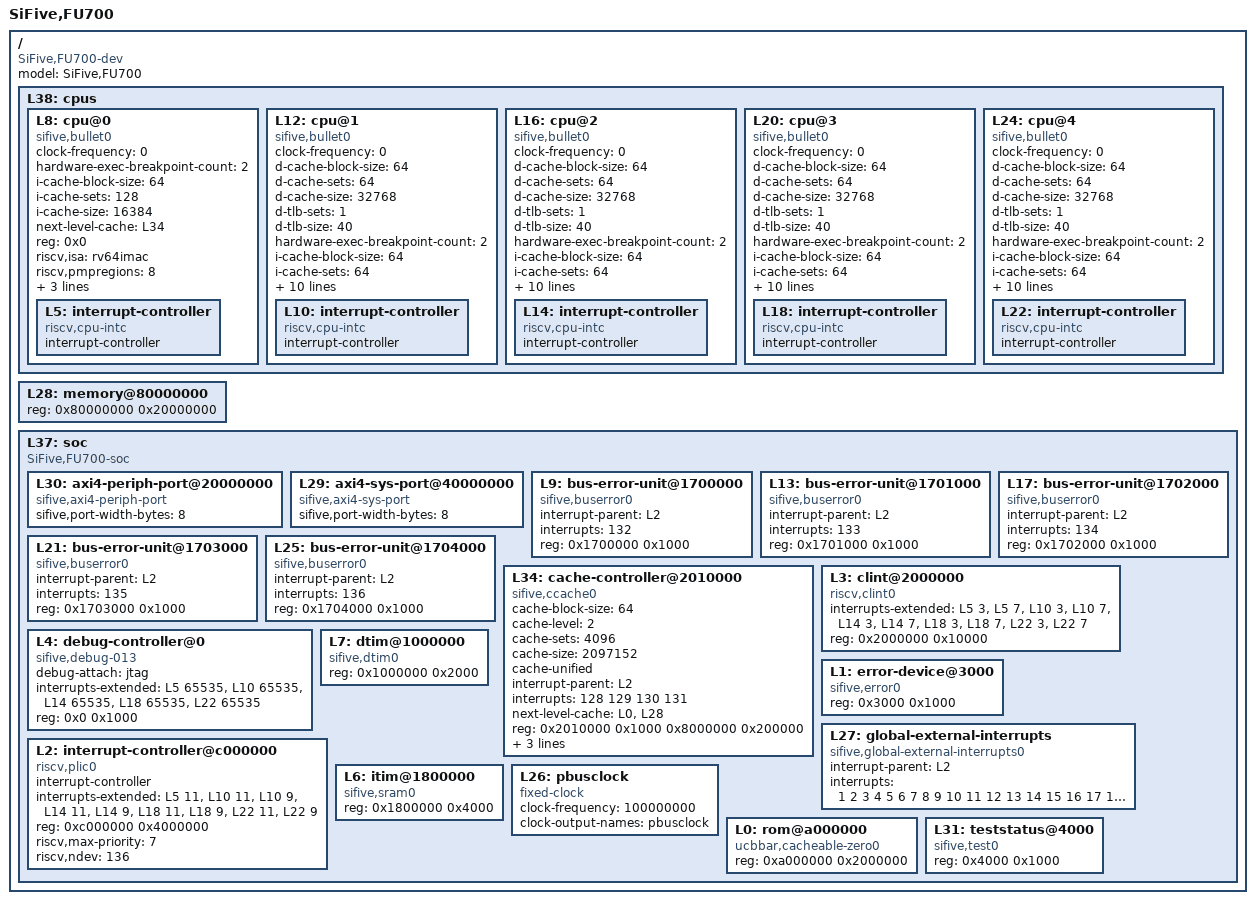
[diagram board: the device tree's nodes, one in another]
/dts-v1/;

/ {
	#address-cells = <1>;
	#size-cells = <1>;
	compatible = "SiFive,FU700-dev", "fu700-dev", "sifive-dev";
	model = "SiFive,FU700";
	L38: cpus {
		#address-cells = <1>;
		#size-cells = <0>;
		L8: cpu@0 {
			clock-frequency = <0>;
			compatible = "sifive,bullet0", "riscv";
			device_type = "cpu";
			hardware-exec-breakpoint-count = <2>;
			i-cache-block-size = <64>;
			i-cache-sets = <128>;
			i-cache-size = <16384>;
			next-level-cache = <&L34>;
			reg = <0x0>;
			riscv,isa = "rv64imac";
			riscv,pmpregions = <8>;
			sifive,dtim = <&L7>;
			sifive,itim = <&L6>;
			status = "okay";
			timebase-frequency = <1000000>;
			L5: interrupt-controller {
				#interrupt-cells = <1>;
				compatible = "riscv,cpu-intc";
				interrupt-controller;
			};
		};
		L12: cpu@1 {
			clock-frequency = <0>;
			compatible = "sifive,bullet0", "riscv";
			d-cache-block-size = <64>;
			d-cache-sets = <64>;
			d-cache-size = <32768>;
			d-tlb-sets = <1>;
			d-tlb-size = <40>;
			device_type = "cpu";
			hardware-exec-breakpoint-count = <2>;
			i-cache-block-size = <64>;
			i-cache-sets = <64>;
			i-cache-size = <32768>;
			i-tlb-sets = <1>;
			i-tlb-size = <40>;
			mmu-type = "riscv,sv39";
			next-level-cache = <&L34>;
			reg = <0x1>;
			riscv,isa = "rv64imafdc";
			riscv,pmpregions = <8>;
			status = "okay";
			timebase-frequency = <1000000>;
			tlb-split;
			L10: interrupt-controller {
				#interrupt-cells = <1>;
				compatible = "riscv,cpu-intc";
				interrupt-controller;
			};
		};
		L16: cpu@2 {
			clock-frequency = <0>;
			compatible = "sifive,bullet0", "riscv";
			d-cache-block-size = <64>;
			d-cache-sets = <64>;
			d-cache-size = <32768>;
			d-tlb-sets = <1>;
			d-tlb-size = <40>;
			device_type = "cpu";
			hardware-exec-breakpoint-count = <2>;
			i-cache-block-size = <64>;
			i-cache-sets = <64>;
			i-cache-size = <32768>;
			i-tlb-sets = <1>;
			i-tlb-size = <40>;
			mmu-type = "riscv,sv39";
			next-level-cache = <&L34>;
			reg = <0x2>;
			riscv,isa = "rv64imafdc";
			riscv,pmpregions = <8>;
			status = "okay";
			timebase-frequency = <1000000>;
			tlb-split;
			L14: interrupt-controller {
				#interrupt-cells = <1>;
				compatible = "riscv,cpu-intc";
				interrupt-controller;
			};
		};
		L20: cpu@3 {
			clock-frequency = <0>;
			compatible = "sifive,bullet0", "riscv";
			d-cache-block-size = <64>;
			d-cache-sets = <64>;
			d-cache-size = <32768>;
			d-tlb-sets = <1>;
			d-tlb-size = <40>;
			device_type = "cpu";
			hardware-exec-breakpoint-count = <2>;
			i-cache-block-size = <64>;
			i-cache-sets = <64>;
			i-cache-size = <32768>;
			i-tlb-sets = <1>;
			i-tlb-size = <40>;
			mmu-type = "riscv,sv39";
			next-level-cache = <&L34>;
			reg = <0x3>;
			riscv,isa = "rv64imafdc";
			riscv,pmpregions = <8>;
			status = "okay";
			timebase-frequency = <1000000>;
			tlb-split;
			L18: interrupt-controller {
				#interrupt-cells = <1>;
				compatible = "riscv,cpu-intc";
				interrupt-controller;
			};
		};
		L24: cpu@4 {
			clock-frequency = <0>;
			compatible = "sifive,bullet0", "riscv";
			d-cache-block-size = <64>;
			d-cache-sets = <64>;
			d-cache-size = <32768>;
			d-tlb-sets = <1>;
			d-tlb-size = <40>;
			device_type = "cpu";
			hardware-exec-breakpoint-count = <2>;
			i-cache-block-size = <64>;
			i-cache-sets = <64>;
			i-cache-size = <32768>;
			i-tlb-sets = <1>;
			i-tlb-size = <40>;
			mmu-type = "riscv,sv39";
			next-level-cache = <&L34>;
			reg = <0x4>;
			riscv,isa = "rv64imafdc";
			riscv,pmpregions = <8>;
			status = "okay";
			timebase-frequency = <1000000>;
			tlb-split;
			L22: interrupt-controller {
				#interrupt-cells = <1>;
				compatible = "riscv,cpu-intc";
				interrupt-controller;
			};
		};
	};
	L28: memory@80000000 {
		device_type = "memory";
		reg = <0x80000000 0x20000000>;
	};
	L37: soc {
		#address-cells = <1>;
		#size-cells = <1>;
		compatible = "SiFive,FU700-soc", "fu700-soc", "sifive-soc", "simple-bus";
		ranges;
		L30: axi4-periph-port@20000000 {
			#address-cells = <1>;
			#size-cells = <1>;
			compatible = "sifive,axi4-periph-port", "sifive,axi4-port", "sifive,periph-port", "simple-external-bus", "simple-bus";
			ranges = <0x20000000 0x20000000 0x10000000>;
			sifive,port-width-bytes = <8>;
		};
		L29: axi4-sys-port@40000000 {
			#address-cells = <1>;
			#size-cells = <1>;
			compatible = "sifive,axi4-sys-port", "sifive,axi4-port", "sifive,sys-port", "simple-external-bus", "simple-bus";
			ranges = <0x40000000 0x40000000 0x10000000>;
			sifive,port-width-bytes = <8>;
		};
		L9: bus-error-unit@1700000 {
			compatible = "sifive,buserror0";
			interrupt-parent = <&L2>;
			interrupts = <132>;
			reg = <0x1700000 0x1000>;
			reg-names = "control";
		};
		L13: bus-error-unit@1701000 {
			compatible = "sifive,buserror0";
			interrupt-parent = <&L2>;
			interrupts = <133>;
			reg = <0x1701000 0x1000>;
			reg-names = "control";
		};
		L17: bus-error-unit@1702000 {
			compatible = "sifive,buserror0";
			interrupt-parent = <&L2>;
			interrupts = <134>;
			reg = <0x1702000 0x1000>;
			reg-names = "control";
		};
		L21: bus-error-unit@1703000 {
			compatible = "sifive,buserror0";
			interrupt-parent = <&L2>;
			interrupts = <135>;
			reg = <0x1703000 0x1000>;
			reg-names = "control";
		};
		L25: bus-error-unit@1704000 {
			compatible = "sifive,buserror0";
			interrupt-parent = <&L2>;
			interrupts = <136>;
			reg = <0x1704000 0x1000>;
			reg-names = "control";
		};
		L34: cache-controller@2010000 {
			cache-block-size = <64>;
			cache-level = <2>;
			cache-sets = <4096>;
			cache-size = <2097152>;
			cache-unified;
			compatible = "sifive,ccache0", "cache";
			interrupt-parent = <&L2>;
			interrupts = <128 129 130 131>;
			next-level-cache = <&L0 &L28>;
			reg = <0x2010000 0x1000 0x8000000 0x200000>;
			reg-names = "control", "sideband";
			sifive,a-mshr-count = <6>;
			sifive,bank-count = <2>;
			sifive,ecc-granularity = <8>;
		};
		L3: clint@2000000 {
			compatible = "riscv,clint0";
			interrupts-extended = <&L5 3 &L5 7 &L10 3 &L10 7 &L14 3 &L14 7 &L18 3 &L18 7 &L22 3 &L22 7>;
			reg = <0x2000000 0x10000>;
			reg-names = "control";
		};
		L4: debug-controller@0 {
			compatible = "sifive,debug-013", "riscv,debug-013";
			debug-attach = "jtag";
			interrupts-extended = <&L5 65535 &L10 65535 &L14 65535 &L18 65535 &L22 65535>;
			reg = <0x0 0x1000>;
			reg-names = "control";
		};
		L7: dtim@1000000 {
			compatible = "sifive,dtim0";
			reg = <0x1000000 0x2000>;
			reg-names = "mem";
		};
		L1: error-device@3000 {
			compatible = "sifive,error0";
			reg = <0x3000 0x1000>;
		};
		L27: global-external-interrupts {
			compatible = "sifive,global-external-interrupts0";
			interrupt-parent = <&L2>;
			interrupts = <1 2 3 4 5 6 7 8 9 10 11 12 13 14 15 16 17 18 19 20 21 22 23 24 25 26 27 28 29 30 31 32 33 34 35 36 37 38 39 40 41 42 43 44 45 46 47 48 49 50 51 52 53 54 55 56 57 58 59 60 61 62 63 64 65 66 67 68 69 70 71 72 73 74 75 76 77 78 79 80 81 82 83 84 85 86 87 88 89 90 91 92 93 94 95 96 97 98 99 100 101 102 103 104 105 106 107 108 109 110 111 112 113 114 115 116 117 118 119 120 121 122 123 124 125 126 127>;
		};
		L2: interrupt-controller@c000000 {
			#interrupt-cells = <1>;
			compatible = "riscv,plic0";
			interrupt-controller;
			interrupts-extended = <&L5 11 &L10 11 &L10 9 &L14 11 &L14 9 &L18 11 &L18 9 &L22 11 &L22 9>;
			reg = <0xc000000 0x4000000>;
			reg-names = "control";
			riscv,max-priority = <7>;
			riscv,ndev = <136>;
		};
		L6: itim@1800000 {
			compatible = "sifive,sram0";
			reg = <0x1800000 0x4000>;
			reg-names = "mem";
		};
		L26: pbusclock {
			#clock-cells = <0>;
			clock-frequency = <100000000>;
			clock-output-names = "pbusclock";
			compatible = "fixed-clock";
		};
		L0: rom@a000000 {
			compatible = "ucbbar,cacheable-zero0";
			reg = <0xa000000 0x2000000>;
		};
		L31: teststatus@4000 {
			compatible = "sifive,test0";
			reg = <0x4000 0x1000>;
			reg-names = "control";
		};
	};
};
